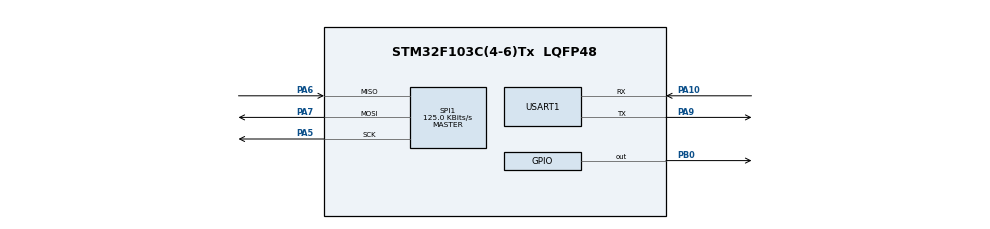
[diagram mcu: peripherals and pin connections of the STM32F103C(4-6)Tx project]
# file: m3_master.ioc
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Mcu.Family=STM32F1
Mcu.Name=STM32F103C(4-6)Tx
Mcu.Package=LQFP48
NVIC.PriorityGroup=NVIC_PRIORITYGROUP_4
PA10.Mode=Asynchronous
PA10.Signal=USART1_RX
PA5.Mode=Full_Duplex_Master
PA5.Signal=SPI1_SCK
PA6.Mode=Full_Duplex_Master
PA6.Signal=SPI1_MISO
PA7.Mode=Full_Duplex_Master
PA7.Signal=SPI1_MOSI
PA9.Mode=Asynchronous
PA9.Signal=USART1_TX
PB0.Signal=GPIO_Output
ProjectManager.HeapSize=0x200
ProjectManager.StackSize=0x400
ProjectManager.TargetToolchain=STM32CubeIDE
RCC.APB1Freq_Value=8000000
RCC.APB2Freq_Value=8000000
SPI1.BaudRatePrescaler=SPI_BAUDRATEPRESCALER_64
SPI1.CalculateBaudRate=125.0 KBits/s
SPI1.Direction=SPI_DIRECTION_2LINES
SPI1.Mode=SPI_MODE_MASTER
SPI1.VirtualType=VM_MASTER
USART1.VirtualMode=VM_ASYNC
VP_SYS_VS_ND.Mode=No_Debug
board=custom

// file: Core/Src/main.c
/* USER CODE BEGIN Header */
/**
  ******************************************************************************
  * @file           : main.c
  * @brief          : Main program body
  ******************************************************************************
  * @attention
  *
  * Copyright (c) 2026 STMicroelectronics.
  * All rights reserved.
  *
  * This software is licensed under terms that can be found in the LICENSE file
  * in the root directory of this software component.
  * If no LICENSE file comes with this software, it is provided AS-IS.
  *
  ******************************************************************************
  */
/* USER CODE END Header */
#include "main.h"
#include <stdio.h>
#include <string.h>
/* USER CODE BEGIN Includes */
uint8_t user_choice = 0;
uint8_t tx_data[3] = {0};
uint8_t rx_data[3] = {0};
char uart_buf[100];
uint16_t raw_speed = 0;
uint16_t raw_voltage = 0;
float voltage = 0.0;
float speed = 0.0;
/* USER CODE END Includes */

SPI_HandleTypeDef hspi1;

UART_HandleTypeDef huart1;

void SystemClock_Config(void);
static void MX_GPIO_Init(void);
static void MX_SPI1_Init(void);
static void MX_USART1_UART_Init(void);

int main(void)
{

  /* USER CODE BEGIN 1 */
	HAL_GPIO_WritePin(GPIOB, GPIO_PIN_0, GPIO_PIN_SET);
  /* USER CODE END 1 */

  /* MCU Configuration--------------------------------------------------------*/

  /* Reset of all peripherals, Initializes the Flash interface and the Systick. */
  HAL_Init();

  /* Configure the system clock */
  SystemClock_Config();

  /* Initialize all configured peripherals */
  MX_GPIO_Init();
  MX_SPI1_Init();
  MX_USART1_UART_Init();

  /* Infinite loop */
  while (1)
  {
	  sprintf(uart_buf, "\r\nEnter Case ID (1-5): ");
	      HAL_UART_Transmit(&huart1, (uint8_t*)uart_buf, strlen(uart_buf), 100);

	      HAL_UART_Receive(&huart1, &user_choice, 1, HAL_MAX_DELAY);

	      uint8_t case_num = user_choice - '0';

	      if (case_num >= 1 && case_num <= 5) {
	          tx_data[0] = case_num;

	          HAL_GPIO_WritePin(GPIOB, GPIO_PIN_0, GPIO_PIN_RESET);
	          HAL_SPI_TransmitReceive(&hspi1, tx_data, rx_data, 3, 1000);
	          HAL_GPIO_WritePin(GPIOB, GPIO_PIN_0, GPIO_PIN_SET);

	          HAL_Delay(10);

	          HAL_GPIO_WritePin(GPIOB, GPIO_PIN_0, GPIO_PIN_RESET);
	          HAL_SPI_TransmitReceive(&hspi1, tx_data, rx_data, 3, 1000);
	          HAL_GPIO_WritePin(GPIOB, GPIO_PIN_0, GPIO_PIN_SET);

	          raw_voltage = ((rx_data[0] << 4) | (rx_data[1] >> 4));
	          raw_speed = (((rx_data[1] & 0x0F) << 8) | rx_data[2]);

	          voltage = raw_voltage / 10.0f;
	          speed = (float)raw_speed;

	          sprintf(uart_buf, "\r\nReceived -> Voltage: %.1f V | Speed: %.0f km/h\r\n", voltage, speed);
	          HAL_UART_Transmit(&huart1, (uint8_t*)uart_buf, strlen(uart_buf), 100);
	      } else {
	          sprintf(uart_buf, "\r\nInvalid Case ID! Try again.\r\n");
	          HAL_UART_Transmit(&huart1, (uint8_t*)uart_buf, strlen(uart_buf), 100);
	      }

	      HAL_Delay(500);
  }
}

void SystemClock_Config(void)
{
  RCC_OscInitTypeDef RCC_OscInitStruct = {0};
  RCC_ClkInitTypeDef RCC_ClkInitStruct = {0};

  /** Initializes the RCC Oscillators according to the specified parameters
  * in the RCC_OscInitTypeDef structure.
  */
  RCC_OscInitStruct.OscillatorType = RCC_OSCILLATORTYPE_HSI;
  RCC_OscInitStruct.HSIState = RCC_HSI_ON;
  RCC_OscInitStruct.HSICalibrationValue = RCC_HSICALIBRATION_DEFAULT;
  RCC_OscInitStruct.PLL.PLLState = RCC_PLL_NONE;
  if (HAL_RCC_OscConfig(&RCC_OscInitStruct) != HAL_OK)
  {
    Error_Handler();
  }

  /** Initializes the CPU, AHB and APB buses clocks
  */
  RCC_ClkInitStruct.ClockType = RCC_CLOCKTYPE_HCLK|RCC_CLOCKTYPE_SYSCLK
                              |RCC_CLOCKTYPE_PCLK1|RCC_CLOCKTYPE_PCLK2;
  RCC_ClkInitStruct.SYSCLKSource = RCC_SYSCLKSOURCE_HSI;
  RCC_ClkInitStruct.AHBCLKDivider = RCC_SYSCLK_DIV1;
  RCC_ClkInitStruct.APB1CLKDivider = RCC_HCLK_DIV1;
  RCC_ClkInitStruct.APB2CLKDivider = RCC_HCLK_DIV1;

  if (HAL_RCC_ClockConfig(&RCC_ClkInitStruct, FLASH_LATENCY_0) != HAL_OK)
  {
    Error_Handler();
  }
}

static void MX_SPI1_Init(void)
{

  /* SPI1 parameter configuration*/
  hspi1.Instance = SPI1;
  hspi1.Init.Mode = SPI_MODE_MASTER;
  hspi1.Init.Direction = SPI_DIRECTION_2LINES;
  hspi1.Init.DataSize = SPI_DATASIZE_8BIT;
  hspi1.Init.CLKPolarity = SPI_POLARITY_LOW;
  hspi1.Init.CLKPhase = SPI_PHASE_1EDGE;
  hspi1.Init.NSS = SPI_NSS_SOFT;
  hspi1.Init.BaudRatePrescaler = SPI_BAUDRATEPRESCALER_64;
  hspi1.Init.FirstBit = SPI_FIRSTBIT_MSB;
  hspi1.Init.TIMode = SPI_TIMODE_DISABLE;
  hspi1.Init.CRCCalculation = SPI_CRCCALCULATION_DISABLE;
  hspi1.Init.CRCPolynomial = 10;
  if (HAL_SPI_Init(&hspi1) != HAL_OK)
  {
    Error_Handler();
  }

}

static void MX_USART1_UART_Init(void)
{

  huart1.Instance = USART1;
  huart1.Init.BaudRate = 115200;
  huart1.Init.WordLength = UART_WORDLENGTH_8B;
  huart1.Init.StopBits = UART_STOPBITS_1;
  huart1.Init.Parity = UART_PARITY_NONE;
  huart1.Init.Mode = UART_MODE_TX_RX;
  huart1.Init.HwFlowCtl = UART_HWCONTROL_NONE;
  huart1.Init.OverSampling = UART_OVERSAMPLING_16;
  if (HAL_UART_Init(&huart1) != HAL_OK)
  {
    Error_Handler();
  }

}

static void MX_GPIO_Init(void)
{
  GPIO_InitTypeDef GPIO_InitStruct = {0};

  /* GPIO Ports Clock Enable */
  __HAL_RCC_GPIOA_CLK_ENABLE();
  __HAL_RCC_GPIOB_CLK_ENABLE();

  /*Configure GPIO pin Output Level */
  HAL_GPIO_WritePin(GPIOB, GPIO_PIN_0, GPIO_PIN_RESET);

  /*Configure GPIO pin : PB0 */
  GPIO_InitStruct.Pin = GPIO_PIN_0;
  GPIO_InitStruct.Mode = GPIO_MODE_OUTPUT_PP;
  GPIO_InitStruct.Pull = GPIO_NOPULL;
  GPIO_InitStruct.Speed = GPIO_SPEED_FREQ_LOW;
  HAL_GPIO_Init(GPIOB, &GPIO_InitStruct);

}

void Error_Handler(void)
{
  __disable_irq();
  while (1)
  {
  }
}
